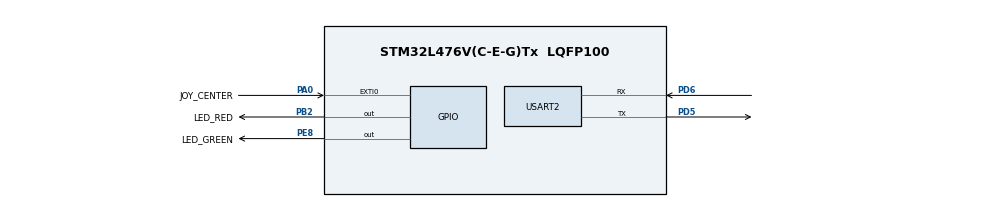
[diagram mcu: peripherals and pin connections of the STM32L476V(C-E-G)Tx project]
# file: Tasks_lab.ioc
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FREERTOS.Tasks01=Task1,0,128,StartTask1,Default,NULL,Dynamic,NULL,NULL;Task2,0,128,StartTask2,Default,NULL,Dynamic,NULL,NULL
Mcu.Family=STM32L4
Mcu.Name=STM32L476V(C-E-G)Tx
Mcu.Package=LQFP100
NVIC.EXTI0_IRQn=true\:5\:0\:false\:false\:true\:true\:true
NVIC.PriorityGroup=NVIC_PRIORITYGROUP_4
NVIC.TIM6_DAC_IRQn=true\:0\:0\:false\:false\:true\:false\:false
NVIC.TimeBase=TIM6_DAC_IRQn
NVIC.TimeBaseIP=TIM6
PA0.GPIO_Label=JOY_CENTER
PA0.Signal=GPXTI0
PA13\ (JTMS-SWDIO).Mode=Serial_Wire
PA13\ (JTMS-SWDIO).Signal=SYS_JTMS-SWDIO
PA14\ (JTCK-SWCLK).Mode=Serial_Wire
PA14\ (JTCK-SWCLK).Signal=SYS_JTCK-SWCLK
PB2.GPIO_Label=LED_RED
PB2.Signal=GPIO_Output
PD5.Mode=Asynchronous
PD5.Signal=USART2_TX
PD6.Mode=Asynchronous
PD6.Signal=USART2_RX
PE8.GPIO_Label=LED_GREEN
PE8.Signal=GPIO_Output
ProjectManager.HeapSize=0x200
ProjectManager.StackSize=0x400
ProjectManager.TargetToolchain=TrueSTUDIO
RCC.HSE_VALUE=8000000
RCC.HSI_VALUE=16000000
RCC.LSE_VALUE=32768
RCC.MSI_VALUE=4000000
RCC.VCOOutputFreq_Value=32000000
USART2.VirtualMode-Asynchronous=VM_ASYNC
VP_FREERTOS_VS_ENABLE.Mode=Enabled
VP_SYS_VS_tim6.Mode=TIM6
board=custom

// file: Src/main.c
/* USER CODE BEGIN Header */
/**
  ******************************************************************************
  * @file           : main.c
  * @brief          : Main program body
  ******************************************************************************
  * This notice applies to any and all portions of this file
  * that are not between comment pairs USER CODE BEGIN and
  * USER CODE END. Other portions of this file, whether
  * inserted by the user or by software development tools
  * are owned by their respective copyright owners.
  *
  * Copyright (c) 2019 STMicroelectronics International N.V.
  * All rights reserved.
  *
  * Redistribution and use in source and binary forms, with or without
  * modification, are permitted, provided that the following conditions are met:
  *
  * 1. Redistribution of source code must retain the above copyright notice,
  *    this list of conditions and the following disclaimer.
  * 2. Redistributions in binary form must reproduce the above copyright notice,
  *    this list of conditions and the following disclaimer in the documentation
  *    and/or other materials provided with the distribution.
  * 3. Neither the name of STMicroelectronics nor the names of other
  *    contributors to this software may be used to endorse or promote products
  *    derived from this software without specific written permission.
  * 4. This software, including modifications and/or derivative works of this
  *    software, must execute solely and exclusively on microcontroller or
  *    microprocessor devices manufactured by or for STMicroelectronics.
  * 5. Redistribution and use of this software other than as permitted under
  *    this license is void and will automatically terminate your rights under
  *    this license.
  *
  * THIS SOFTWARE IS PROVIDED BY STMICROELECTRONICS AND CONTRIBUTORS "AS IS"
  * AND ANY EXPRESS, IMPLIED OR STATUTORY WARRANTIES, INCLUDING, BUT NOT
  * LIMITED TO, THE IMPLIED WARRANTIES OF MERCHANTABILITY, FITNESS FOR A
  * PARTICULAR PURPOSE AND NON-INFRINGEMENT OF THIRD PARTY INTELLECTUAL PROPERTY
  * RIGHTS ARE DISCLAIMED TO THE FULLEST EXTENT PERMITTED BY LAW. IN NO EVENT
  * SHALL STMICROELECTRONICS OR CONTRIBUTORS BE LIABLE FOR ANY DIRECT, INDIRECT,
  * INCIDENTAL, SPECIAL, EXEMPLARY, OR CONSEQUENTIAL DAMAGES (INCLUDING, BUT NOT
  * LIMITED TO, PROCUREMENT OF SUBSTITUTE GOODS OR SERVICES; LOSS OF USE, DATA,
  * OR PROFITS; OR BUSINESS INTERRUPTION) HOWEVER CAUSED AND ON ANY THEORY OF
  * LIABILITY, WHETHER IN CONTRACT, STRICT LIABILITY, OR TORT (INCLUDING
  * NEGLIGENCE OR OTHERWISE) ARISING IN ANY WAY OUT OF THE USE OF THIS SOFTWARE,
  * EVEN IF ADVISED OF THE POSSIBILITY OF SUCH DAMAGE.
  *
  ******************************************************************************
  */
/* USER CODE END Header */

#include "main.h"
#include "cmsis_os.h"

/* USER CODE BEGIN Includes */
#include <stdio.h>
/* USER CODE END Includes */

UART_HandleTypeDef huart2;

osThreadId Task1Handle;
osThreadId Task2Handle;

void SystemClock_Config(void);
static void MX_GPIO_Init(void);
static void MX_USART2_UART_Init(void);
void StartTask1(void const * argument);
void StartTask2(void const * argument);

/* USER CODE BEGIN 0 */
int _write(int file, char *ptr, int len)
{
  HAL_UART_Transmit(&huart2,(uint8_t *)ptr,len,10);
  return len;
}
/* USER CODE END 0 */

int main(void)
{

  /* MCU Configuration--------------------------------------------------------*/

  /* Reset of all peripherals, Initializes the Flash interface and the Systick. */
  HAL_Init();

  /* Configure the system clock */
  SystemClock_Config();

  /* Initialize all configured peripherals */
  MX_GPIO_Init();
  MX_USART2_UART_Init();
  /* USER CODE BEGIN 2 */
  printf("Application start\n\r");//some terminals like in TrueStudio do not do automatic CR so \r is needed
  /* USER CODE END 2 */

  /* Create the thread(s) */
  /* definition and creation of Task1 */
  osThreadDef(Task1, StartTask1, osPriorityNormal, 0, 128);
  Task1Handle = osThreadCreate(osThread(Task1), NULL);

  /* definition and creation of Task2 */
  osThreadDef(Task2, StartTask2, osPriorityNormal, 0, 128);
  Task2Handle = osThreadCreate(osThread(Task2), NULL);

  /* Start scheduler */
  osKernelStart();

  /* We should never get here as control is now taken by the scheduler */

  /* Infinite loop */
  while (1)
  {

  }
}

void SystemClock_Config(void)
{
  RCC_OscInitTypeDef RCC_OscInitStruct = {0};
  RCC_ClkInitTypeDef RCC_ClkInitStruct = {0};
  RCC_PeriphCLKInitTypeDef PeriphClkInit = {0};

  /**Initializes the CPU, AHB and APB busses clocks
  */
  RCC_OscInitStruct.OscillatorType = RCC_OSCILLATORTYPE_MSI;
  RCC_OscInitStruct.MSIState = RCC_MSI_ON;
  RCC_OscInitStruct.MSICalibrationValue = 0;
  RCC_OscInitStruct.MSIClockRange = RCC_MSIRANGE_6;
  RCC_OscInitStruct.PLL.PLLState = RCC_PLL_NONE;
  if (HAL_RCC_OscConfig(&RCC_OscInitStruct) != HAL_OK)
  {
    Error_Handler();
  }
  /**Initializes the CPU, AHB and APB busses clocks
  */
  RCC_ClkInitStruct.ClockType = RCC_CLOCKTYPE_HCLK|RCC_CLOCKTYPE_SYSCLK
                              |RCC_CLOCKTYPE_PCLK1|RCC_CLOCKTYPE_PCLK2;
  RCC_ClkInitStruct.SYSCLKSource = RCC_SYSCLKSOURCE_MSI;
  RCC_ClkInitStruct.AHBCLKDivider = RCC_SYSCLK_DIV1;
  RCC_ClkInitStruct.APB1CLKDivider = RCC_HCLK_DIV1;
  RCC_ClkInitStruct.APB2CLKDivider = RCC_HCLK_DIV1;

  if (HAL_RCC_ClockConfig(&RCC_ClkInitStruct, FLASH_LATENCY_0) != HAL_OK)
  {
    Error_Handler();
  }
  PeriphClkInit.PeriphClockSelection = RCC_PERIPHCLK_USART2;
  PeriphClkInit.Usart2ClockSelection = RCC_USART2CLKSOURCE_PCLK1;
  if (HAL_RCCEx_PeriphCLKConfig(&PeriphClkInit) != HAL_OK)
  {
    Error_Handler();
  }
  /**Configure the main internal regulator output voltage
  */
  if (HAL_PWREx_ControlVoltageScaling(PWR_REGULATOR_VOLTAGE_SCALE1) != HAL_OK)
  {
    Error_Handler();
  }
}

static void MX_USART2_UART_Init(void)
{

  huart2.Instance = USART2;
  huart2.Init.BaudRate = 115200;
  huart2.Init.WordLength = UART_WORDLENGTH_8B;
  huart2.Init.StopBits = UART_STOPBITS_1;
  huart2.Init.Parity = UART_PARITY_NONE;
  huart2.Init.Mode = UART_MODE_TX_RX;
  huart2.Init.HwFlowCtl = UART_HWCONTROL_NONE;
  huart2.Init.OverSampling = UART_OVERSAMPLING_16;
  huart2.Init.OneBitSampling = UART_ONE_BIT_SAMPLE_DISABLE;
  huart2.AdvancedInit.AdvFeatureInit = UART_ADVFEATURE_NO_INIT;
  if (HAL_UART_Init(&huart2) != HAL_OK)
  {
    Error_Handler();
  }

}

static void MX_GPIO_Init(void)
{
  GPIO_InitTypeDef GPIO_InitStruct = {0};

  /* GPIO Ports Clock Enable */
  __HAL_RCC_GPIOA_CLK_ENABLE();
  __HAL_RCC_GPIOB_CLK_ENABLE();
  __HAL_RCC_GPIOE_CLK_ENABLE();
  __HAL_RCC_GPIOD_CLK_ENABLE();

  /*Configure GPIO pin Output Level */
  HAL_GPIO_WritePin(LED_RED_GPIO_Port, LED_RED_Pin, GPIO_PIN_RESET);

  /*Configure GPIO pin Output Level */
  HAL_GPIO_WritePin(LED_GREEN_GPIO_Port, LED_GREEN_Pin, GPIO_PIN_RESET);

  /*Configure GPIO pin : JOY_CENTER_Pin */
  GPIO_InitStruct.Pin = JOY_CENTER_Pin;
  GPIO_InitStruct.Mode = GPIO_MODE_IT_RISING;
  GPIO_InitStruct.Pull = GPIO_NOPULL;
  HAL_GPIO_Init(JOY_CENTER_GPIO_Port, &GPIO_InitStruct);

  /*Configure GPIO pin : LED_RED_Pin */
  GPIO_InitStruct.Pin = LED_RED_Pin;
  GPIO_InitStruct.Mode = GPIO_MODE_OUTPUT_PP;
  GPIO_InitStruct.Pull = GPIO_NOPULL;
  GPIO_InitStruct.Speed = GPIO_SPEED_FREQ_LOW;
  HAL_GPIO_Init(LED_RED_GPIO_Port, &GPIO_InitStruct);

  /*Configure GPIO pin : LED_GREEN_Pin */
  GPIO_InitStruct.Pin = LED_GREEN_Pin;
  GPIO_InitStruct.Mode = GPIO_MODE_OUTPUT_PP;
  GPIO_InitStruct.Pull = GPIO_NOPULL;
  GPIO_InitStruct.Speed = GPIO_SPEED_FREQ_LOW;
  HAL_GPIO_Init(LED_GREEN_GPIO_Port, &GPIO_InitStruct);

  /* EXTI interrupt init*/
  HAL_NVIC_SetPriority(EXTI0_IRQn, 5, 0);
  HAL_NVIC_EnableIRQ(EXTI0_IRQn);

}

void StartTask1(void const * argument)
{

  /* USER CODE BEGIN 5 */
  /* Infinite loop */
  for(;;)
  {
	  printf("Task 1\n\r");//some terminals like in TrueStudio do not do automatic CR so \r is needed
	  osDelay(1000);
  }
  /* USER CODE END 5 */
}

void StartTask2(void const * argument)
{
  /* USER CODE BEGIN StartTask2 */
  /* Infinite loop */
  for(;;)
  {
	  printf("Task 2\n\r");	//some terminals like in TrueStudio do not do automatic CR so \r is needed
	  osDelay(1000);
  }
  /* USER CODE END StartTask2 */
}

void HAL_TIM_PeriodElapsedCallback(TIM_HandleTypeDef *htim)
{
  if (htim->Instance == TIM6) {
    HAL_IncTick();
  }
}

void Error_Handler(void)
{
}

/************************ (C) COPYRIGHT STMicroelectronics *****END OF FILE****/
